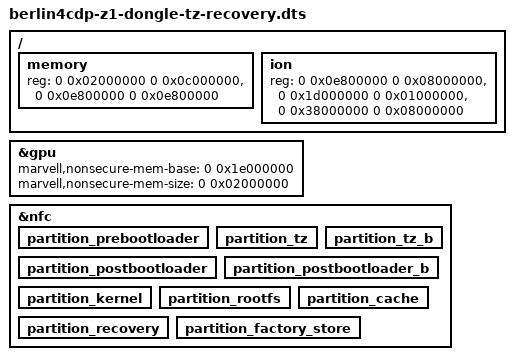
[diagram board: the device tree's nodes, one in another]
/*
 * MARVELL BERLIN4CDP Dongle board device tree source
 *
 * Author:	Hongjun Yuan <hyuan@marvell.com>
 * Copyright (c) 2015 Marvell Technology Group Ltd.
 *		http://www.marvell.com
 *
 * This program is free software; you can redistribute it and/or modify
 * it under the terms of the GNU General Public License version 2 as
 * published by the Free Software Foundation.
*/

/dts-v1/;

/memreserve/ 0x0e800000 0x08000000;

#include "berlin4cdp-dongle-memreserve-tz.dtsi"
#include "berlin4cdp-z1-dongle-common.dtsi"
#include "berlin4cdp-dongle-memlayout-tz.dtsi"

/ {

	memory {
		reg = <0 0x02000000 0 0x0c000000>,
		      <0 0x0e800000 0 0x0e800000>;
	};

	ion {
		reg = <0 0x0e800000 0 0x08000000>, <0 0x1d000000 0 0x01000000>, <0 0x38000000 0 0x08000000>;
	};
};

&gpu {
	marvell,nonsecure-mem-base = <0 0x1e000000>;
	marvell,nonsecure-mem-size = <0 0x02000000>;
};

&nfc {
	status = "okay";

	partition_prebootloader {
		/delete-property/ read-only;
	};

	partition_tz {
		/delete-property/ read-only;
	};

	partition_tz_b {
		/delete-property/ read-only;
	};

	partition_postbootloader {
		/delete-property/ read-only;
	};

	partition_postbootloader_b {
		/delete-property/ read-only;
	};

	partition_kernel {
		/delete-property/ read-only;
	};

	partition_rootfs {
		/delete-property/ read-only;
	};

	partition_cache {
		/delete-property/ read-only;
	};

	partition_recovery {
		/delete-property/ read-only;
	};

	partition_factory_store {
		/delete-property/ read-only;
	};
};
